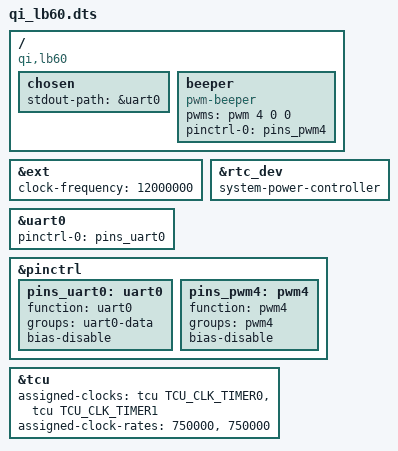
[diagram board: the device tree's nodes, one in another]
// SPDX-License-Identifier: GPL-2.0
/dts-v1/;

#include "jz4740.dtsi"

/ {
	compatible = "qi,lb60", "ingenic,jz4740";

	chosen {
		stdout-path = &uart0;
	};

	beeper {
		compatible = "pwm-beeper";
		pwms = <&pwm 4 0 0>;

		pinctrl-names = "default";
		pinctrl-0 = <&pins_pwm4>;
	};
};

&ext {
	clock-frequency = <12000000>;
};

&rtc_dev {
	system-power-controller;
};

&uart0 {
	pinctrl-names = "default";
	pinctrl-0 = <&pins_uart0>;
};

&pinctrl {
	pins_uart0: uart0 {
		function = "uart0";
		groups = "uart0-data";
		bias-disable;
	};

	pins_pwm4: pwm4 {
		function = "pwm4";
		groups = "pwm4";
		bias-disable;
	};
};

&tcu {
	/* 750 kHz for the system timer and clocksource */
	assigned-clocks = <&tcu TCU_CLK_TIMER0>, <&tcu TCU_CLK_TIMER1>;
	assigned-clock-rates = <750000>, <750000>;
};
